# MSS_RCM register map
Vendor: Texas Instruments
Peripheral module from a debugger description file (folder radar).
Registers are 32-bit, read-write, no defined reset value unless marked. A register's access mark holds for its fields unless they carry their own. Offsets are as the file gives them; lines under a group give offsets from that group; [hi:lo] are bit positions; {n}, {i} and the like mark numbered series; 'fields as' and 'values as' point back to an identical list; <NAME> marks a mode.

## MSS_RCM
0x04 SOFTRST1 access not given
  [7:0] CR4SYSRST — Write 0xAD to assert a MSS CR4 only reset.Self clearing By design reset will happen either lower 4 bit is 0XD or Upper four bit is 0xA.
0x08 SOFTRST2
  [31:24] VIMRST — Write 0xAD to assert a VIM only reset. By design reset will happen either lower 4 bit is 0XD or Upper four bit is 0xA.
0x0C SOFTRST3
  [7:0] WDTRST — Write 0xAD to assert a WDT (RTI used for watch dog) only reset. By design reset will happen either lower 4 bit is 0XD or Upper four bit is 0xA.
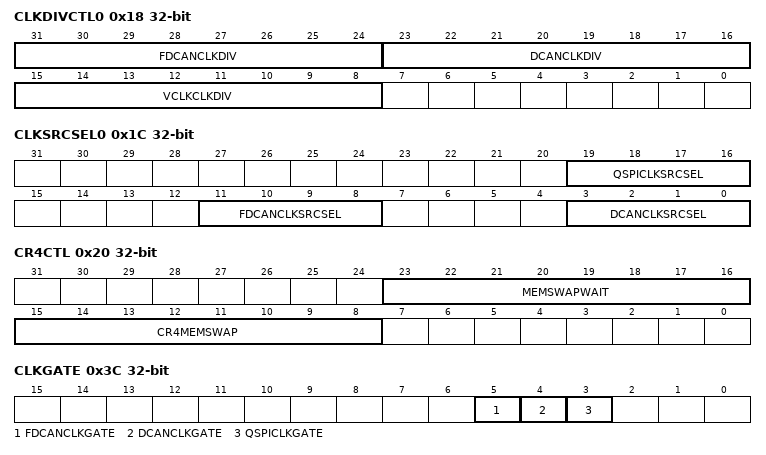
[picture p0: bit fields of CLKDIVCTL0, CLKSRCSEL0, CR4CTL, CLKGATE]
0x18 CLKDIVCTL0
  [31:24] FDCANCLKDIV — Divide value for FDCAN source clock selected by field FDCANCLKSRCSEL in register CLKSRCSEL0 0000_0000 => div1 0000_0001 => div2 | | 1111_1111 => div256
  [23:16] DCANCLKDIV — Divide value for DCAN source clock selected by field DCANCLKSRCSEL in register CLKSRCSEL0 0000_0000 => div1 0000_0001 => div2 | | 1111_1111 => div256
  [15:8] VCLKCLKDIV — Divide value for MSS subsystem source clock selected by field VCLKCLKSRCSEL in register CLKSRCSEL1 0000_0000 => div1 0000_0001 => div2 | | 1111_1111 => div256
0x1C CLKSRCSEL0
  [19:16] QSPICLKSRCSEL — Select clock source for QSPI baud clock 000 => VCLK 001 => RCCLK (10Mhz) 010 => 600Mhz PLL divided clock 011 => 240Mhz PLL divided clock 100 => CPUCLK 101 => RCCLK 110 => REFCLK from ANA (40Mhz or 50 Mhz or 80Mh or 100Mh) 111 => RCCLK
  [11:8] FDCANCLKSRCSEL — Select clock source for FDCANCLKSRCSEL 000 => VCLK 001 => RCCLK (10Mhz) 010 => 600Mhz PLL divided clock 011 => 240Mhz PLL divided clock 100 => CPUCLK 101 => RCCLK 110 => REFCLK from ANA 111 => RCCLK
  [3:0] DCANCLKSRCSEL — Select clock source for DCAN 000 => VCLK 001 => RCCLK (10Mhz) 010 => 600Mhz PLL divided clock 011 => 240Mhz PLL divided clock 100 => CPUCLK 101 => RCCLK 110 => REFCLK from ANA (40Mhz or 50 Mhz or 80Mh or 100Mh) 111 => RCCLK
0x20 CR4CTL
  [23:16] MEMSWAPWAIT — When CR4MEMSWAP is 0xAD : Write 0xAD to this field enable the CR4MEMSWAP only after a CR4 reset – either by writing to CR4SYSRST or by writing to PRCR register in CR4 debug space.
  [15:8] CR4MEMSWAP — Write 0xAD will map the MSS CR4 0x0000_0000 to MSS CR4 TCMA RAM start address.
0x3C CLKGATE
  [5] FDCANCLKGATE — Pre clock divider gate for FDCAN clock. Gates the clock before divider. Gates the clock before divider. 1: Gate the clock. 0: Ungate the clock.
  [4] DCANCLKGATE — Pre clock divider gate for DCAN clock. Gates the clock before divider. Gates the clock before divider. 1: Gate the clock. 0: Ungate the clock.
  [3] QSPICLKGATE — Pre clock divider gate for QSPI clock. Gates the clock before divider. Gates the clock before divider. 1: Gate the clock. 0: Ungate the clock.
0x44 CLKSRCSEL1
  [3:0] VCLKCLKSRCSEL — Select clock source for MSS subsystem VCLK 000 =>CPUCLK from ANA(XTAL 40Mhz or 50 Mhz or 80Mh or 100Mhz/ RCCLK in WU limp mode) 001 => RCCLK (10Mhz) 010 => 600Mhz PLL divided clock 011 => 240Mhz PLL divided clock 100 => RCCLK (10Mhz) 101 => RCCLK (10Mhz) 110 => REFCLK from ANA (40Mhz or 50 Mhz or 80Mh or 100Mh) 111 => RCCLK(10Mhz)
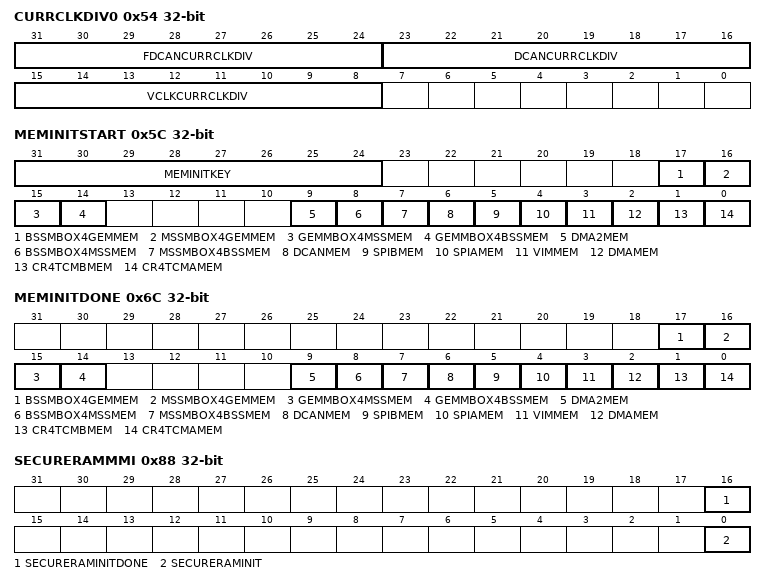
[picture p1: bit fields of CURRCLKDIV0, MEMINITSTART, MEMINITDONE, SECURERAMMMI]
0x54 CURRCLKDIV0 ro
  [31:24] FDCANCURRCLKDIV — Returns Current divide value of FDCAN baud clock divider.
  [23:16] DCANCURRCLKDIV — Returns Current divide value of DCAN baud clock divider.
  [15:8] VCLKCURRCLKDIV — Returns Current divide value of VCLK divider.
0x5C MEMINITSTART access not given
  [31:24] MEMINITKEY rw — Memory hardware initialization global enable key. Write 0XAD to enable MEMINIT.
  [17] BSSMBOX4GEMMEM — Writing '1' will trigger DSS- BSS mailbox initialization.Self clearing
  [16] MSSMBOX4GEMMEM — Writing '1' will trigger DSS- MSS mailbox initialization.Self clearing
  [15] GEMMBOX4MSSMEM — Writing '1' will trigger DSS- MSS mailbox initialization.Self clearing
  [14] GEMMBOX4BSSMEM — Writing '1' will trigger DSS- BSS mailbox initialization.Self clearing
  [9] DMA2MEM — Writing '1' will trigger DMA2 memory initialization.Self clearing
  [8] BSSMBOX4MSSMEM — Writing '1' will trigger MSS- BSS mailbox initialization.Self clearing
  [7] MSSMBOX4BSSMEM — Writing '1' will trigger MSS- BSS mailbox initialization.Self clearing
  [6] DCANMEM — Writing '1' will trigger DCAN memory initialization.Self clearing
  [5] SPIBMEM — Writing '1' will trigger SPIB memory initialization.Self clearing
  [4] SPIAMEM — Writing '1' will trigger SPIA memory initialization.Self clearing
  [3] VIMMEM — Writing '1' will trigger VIM memory initialization.Self clearing
  [2] DMAMEM — Writing '1' will trigger DMA memory initialization.Self clearing
  [1] CR4TCMBMEM — Writing '1' will trigger MSS TCMB memory initialization.Self clearing
  [0] CR4TCMAMEM — Writing '1' will trigger MSS TCMA memory initialization.Self clearing
0x60 CURRCLKDIV1 ro
  [7:0] QSPICURRCLKDIV — Returns Current divide value of QSPI_CLK divider.
0x6C MEMINITDONE ro
  [17] BSSMBOX4GEMMEM — Memory Initialization done status for DSS- BSS mailbox
  [16] MSSMBOX4GEMMEM — Memory Initialization done status for DSS- MSS mailbox
  [15] GEMMBOX4MSSMEM — Memory Initialization done status for DSS- MSS mailbox
  [14] GEMMBOX4BSSMEM — Memory Initialization done status for DSS- BSS mailbox
  [9] DMA2MEM — Memory Initialization done status for MSS DMA2 memory
  [8] BSSMBOX4MSSMEM — Memory Initialization done status for MSS- BSS mailbox
  [7] MSSMBOX4BSSMEM — Memory Initialization done status for MSS- BSS mailbox
  [6] DCANMEM — Memory Initialization done status for DCAN memory
  [5] SPIBMEM — Memory Initialization done status for MSS SPIB memory
  [4] SPIAMEM — Memory Initialization done status for MSS SPIA memory
  [3] VIMMEM — Memory Initialization done status for MSS VIM memory
  [2] DMAMEM — Memory Initialization done status for MSS DMA memory
  [1] CR4TCMBMEM — Memory Initialization done status for MSS TCMB memory
  [0] CR4TCMAMEM — Memory Initialization done status for MSS TCMA memory
0x70 ECCENMSSGEM
  [31:0] ECCENMSSGEM — 7:0 : Writing 0xAD will enable ECC for MSS- DSS mailbox 15:8: Writing 0xAD will enable ECC for MSS- DSS mailbox 18:16 : Write 3'b111 to clear the Address captured because of ECC error in MSS mailbox for GEM 21:19: Write 3'b111 to clear the Address captured because of ECC error. In GEM mailbox for MSS
0x74 ECCCAPTMSSGEM ro
  [31:0] ECCCAPTMSSGEM — 7:0 : mss_mbox4gem_ecc_fault_address 14:8 : mss_mbox4gem_repaired_bit 23:16 : gem_mbox4mss_ecc_fault_address 30:24 : gem_mbox4mss_repaired_bit
0x78 ECCENBSSGEM
  [31:0] ECCENBSSGEM — 7:0 : Writing 0xAD will enable ECC for DSS- BSS mailbox 15:8: Writing 0xAD will enable ECC for DSS- BSS mailbox 18:16 : Write 3'b111 to clear the Address captured because of ECC error in GEM mailbox for BSS 21:19: Write 3'b111 to clear the Address captured because of ECC error in BSS mailbox for GEM
0x7C ECCCAPTBSSGEM ro
  [31:0] ECCCAPTBSSGEM — 7:0 : bss_mbox4gem_ecc_fault_address 14:8 : bss_mbox4gem_repaired_bit 23:16 : gem_mbox4bss_ecc_fault_address 30:24 : gem_mbox4bss_repaired_bit
0x80 USERMODEEN
  [31:0] USERMODEEN — Write 0XADADADAD to enable user mode write access to MSS RCM space.
0x84 NSYSPERUSERMODEN
  [31:0] NSYSPERUSERMODEN — 2:0 : Write 3'b111 to enable user mode access to SPIA 5:3 : Write 3'b111 to enable user mode access to SPIB 10:8 : Write 3'b111 to enable user mode access to GIO 13:11 : Write 3'b111 to enable user mode access to QSPI 18:16 : Write 3'b111 to enable user mode access to SCIA 21:19 : Write 3'b111 to enable user mode access to SCIB 26:24 : Write 3'b111 to enable user mode access to DCAN
0x88 SECURERAMMMI access not given
  [16] SECURERAMINITDONE ro — Memory Initialization done status for Secure Key RAM
  [0] SECURERAMINIT — Writing '1' will trigger Secure Key RAM memory initialization.Self clearing
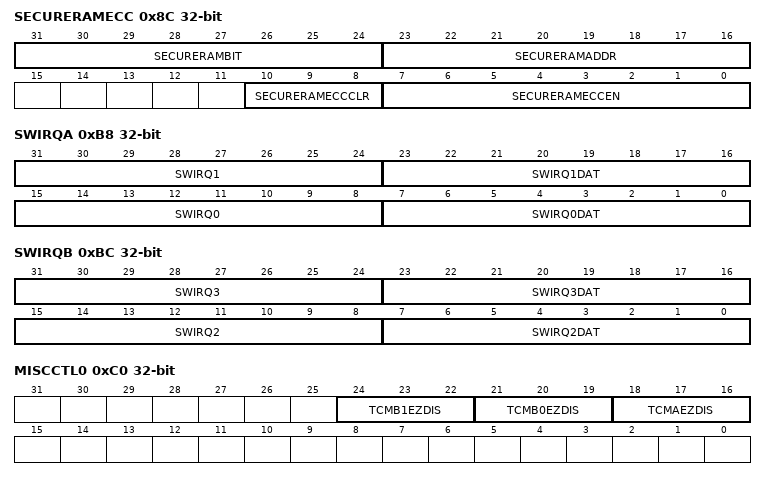
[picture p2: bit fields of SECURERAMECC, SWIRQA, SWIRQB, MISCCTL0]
0x8C SECURERAMECC access per field
  [31:24] SECURERAMBIT ro — Secure key RAM repaired bit
  [23:16] SECURERAMADDR ro — Secure Key RAM_ecc_fault_address
  [10:8] SECURERAMECCCLR rw — 10:8 : Write 3'b111 to clear the Address captured because of ECC error
  [7:0] SECURERAMECCEN rw — 7:0 : Writing 0xAD will enable ECC for Secure key RAM
{0x90+4i} ESMGATE{i} (i=0..2)
  [31:0] ESMGATE{i} — write 4'b111 to Gate [3:0] : Gate ESM group2 line {8i} [7:4] : Gate ESM group2 line {8i+1} [11:8] : Gate ESM group2 line {8i+2} [15:12] : Gate ESM group2 line {8i+3} [19:16] : Gate ESM group2 line {8i+4} [23:20] : Gate ESM group2 line {8i+5} [27:24] : Gate ESM group2 line {8i+6} [31:28] : Gate ESM group2 line {8i+7} Static register setting.Should not be changed on the fly
0x9C ESMGATE3
  [31:0] ESMGATE3 — write 4'b111 to Gate [3:0] : Gate ESM group2 line 16 [7:4] : Gate ESM group2 line 17 [11:8] : Gate ESM group2 line 18 [15:12] : Gate ESM group2 line 19 [19:16] : Gate ESM group2 line 20 [23:20] : Gate ESM group2 line 21 [27:24] : Gate ESM group2 line 22 [31:28] : Gate ESM group2 line 23 Static register setting.Should not be changed on the fly
0xA0 ESMGATE4
  [31:0] ESMGATE4 — write 4'b111 to Gate [3:0] : Gate ESM group3 line 0 [7:4] : Gate ESM group3 line 1 [11:8] : Gate ESM group3 line 2 [15:12] : Gate ESM group3 line 3 [19:16] : Gate ESM group3 line 4 [23:20] : Gate ESM group3 line 5 [27:24] : Gate ESM group3 line 6 [31:28] : Gate ESM group3 line 7 Static register setting.Should not be changed on the fly
0xAC KEY
  [31:0] KEY — Kicker Register. The value 83E7_83E7h must be written as part of the process to unlock the CPU write access to the MSS RCM registers
0xB8 SWIRQA
  [31:24] SWIRQ1 — Write 0XAD to trigger interrupt.
  [23:16] SWIRQ1DAT — Not Used.Reserved
  [15:8] SWIRQ0 — Write 0XAD to trigger interrupt.
  [7:0] SWIRQ0DAT — Not Used.Reserved
0xBC SWIRQB
  [31:24] SWIRQ3 — Write 0XAD to trigger interrupt.
  [23:16] SWIRQ3DAT — Not Used.Reserved
  [15:8] SWIRQ2 — Write 0XAD to trigger interrupt.
  [7:0] SWIRQ2DAT — Not Used.Reserved
0xC0 MISCCTL0
  [24:22] TCMB1EZDIS — Write 111 to make TCMB1 EZ to '1' regardless of Functional value.
  [21:19] TCMB0EZDIS — Write 111 to make TCMB0 EZ to '1' regardless of Functional value.
  [18:16] TCMAEZDIS — Write 111 to make TCMA EZ to '1' regardless of Functional value.
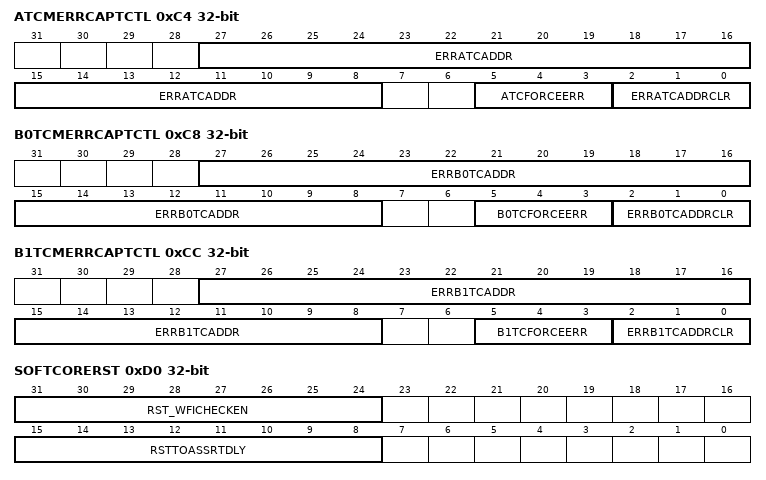
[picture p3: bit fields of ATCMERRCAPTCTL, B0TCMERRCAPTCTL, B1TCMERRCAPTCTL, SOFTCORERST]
0xC4 ATCMERRCAPTCTL access not given
  [27:8] ERRATCADDR ro — TCM address for which parity error happened
  [5:3] ATCFORCEERR rw — Write 111 to force error in TCM address control parity check logic.
  [2:0] ERRATCADDRCLR — When parity error happens on TCM address control path, Latch that captures the address for which error happened is disabled. Write 111 to re-enable the latching.Self clearing
0xC8 B0TCMERRCAPTCTL access not given
  [27:8] ERRB0TCADDR ro — TCM address for which parity error happened
  [5:3] B0TCFORCEERR rw — Write 111 to force error in TCM address control parity check logic.
  [2:0] ERRB0TCADDRCLR — When parity error happens on TCM address control path, Latch that captures the address for which error happened is disabled. Write 111 to re-enable the latching.Self clearing
0xCC B1TCMERRCAPTCTL access not given
  [27:8] ERRB1TCADDR ro — TCM address for which parity error happened
  [5:3] B1TCFORCEERR rw — Write 111 to force error in TCM address control parity check logic.
  [2:0] ERRB1TCADDRCLR — When parity error happens on TCM address control path, Latch that captures the address for which error happened is disabled. Write 111 to re-enable the latching.Self clearing
0xD0 SOFTCORERST
  [31:24] RST_WFICHECKEN — 0xAD : When CR4SYSRST is set, Before asserting the reset to CR4 wait for CR4 to enter WFI. 0X0: Dont wait for WFI
  [15:8] RSTTOASSRTDLY — Wait for programmed number of clock cycle before reset is asserted to CR4.
0xD8 RSTCAUSE ro
  [7:0] RSTCAUSE — Gives cause of MSS reset 0000_1001 : System out of NRESET 0000_1000 : Warm Reset 0000_0010 : MSS only Wdog Reset. 0000_0100 : MSS subsystem reset because of Software trigger. 0010_0000 : CR4 reset because of Software trigger. 0001_0000 : STC reset 0100_0000 : CR4 reset because of writing to PRCR register in CR4 debug space. 1000_0000 : CR4 only Wdog reset
0xDC RSTCAUSECLR access not given
  [7:0] RSTCAUSECLR — Write 0xAD to clear RSTCAUSE.Self clearing
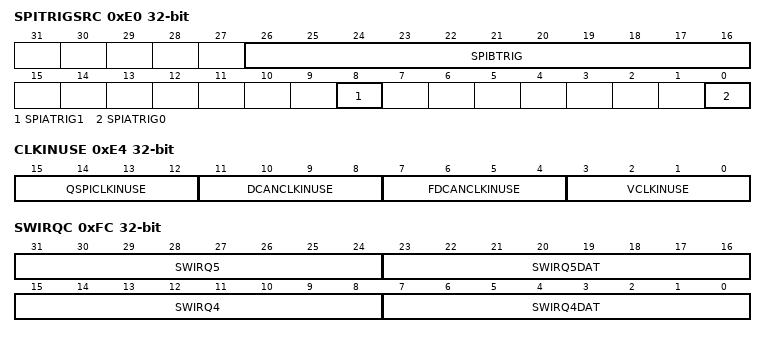
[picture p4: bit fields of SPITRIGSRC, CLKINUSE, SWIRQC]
0xE0 SPITRIGSRC
  [26:16] SPIBTRIG — [20:16] --> Trigger sources for MIBSPIB
  [8] SPIATRIG1 — 1st bit ofTRG_SRC input of SPIA.
  [0] SPIATRIG0 — 0th bit ofTRG_SRC input of SPIA.
0xE4 CLKINUSE ro
  [15:12] QSPICLKINUSE — Current Clock Source Select Mux value for QSPI CLK 000 => VCLK 001 => RCCLK (10Mhz) 010 => 600Mhz PLL divided clock 011 => 240Mhz PLL divided clock 100 => CPUCLK 101 => RCCLK 110 => REFCLK 111 => RCCLK (10Mhz)
  [11:8] DCANCLKINUSE — Current Clock Source Select Mux value for DCAN CLK 000 => VCLK 001 => RCCLK (10Mhz) 010 => 600Mhz PLL divided clock 011 => 240Mhz PLL divided clock 100 => CPUCLK 101 => RCCLK 110 => REFCLK 111 => RCCLK (10Mhz)
  [7:4] FDCANCLKINUSE — Current Clock Source Select Mux value for FDCAN CLK 000 => VCLK 001 => RCCLK (10Mhz) 010 => 600Mhz PLL divided clock 011 => 240Mhz PLL divided clock 100 => CPUCLK 101 => RCCLK 110 => REFCLK 111 => RCCLK (10Mhz)
  [3:0] VCLKINUSE — Current Clock Source Select Mux value for VCLK 000 => CPUCLK (40Mhz or 50 Mhz or 80Mh or 100Mh) 001 => RCCLK (10Mhz) 010 => 600Mhz PLL divided clock 011 => 240Mhz PLL divided clock 101 => RCCLK (10Mhz) 110 => REFCLK 111 => RCCLK (10Mhz)
0xE8 ECCENMSSBSS
  [31:0] ECCENMSSBSS — 7:0 : Writing 0xAD will enable ECC for MSS – BSS mailbox 15:8: Writing 0xAD will enable ECC for MSS – BSS mailbox 18:16 : Write 3'b111 to clear the Address captured because of ECC error in MSS mailbox for BSS 21:19: Write 3'b111 to clear the Address captured because of ECC error. In BSS mailbox for MSS
0xEC ECCCAPTMSSBSS ro
  [31:0] ECCCAPTMSSBSS — 7:0 : mss_mbox4bss_ecc_fault_address 14:8 : mss_mbox4bss_repaired_bit 23:16 : bss_mbox4mss_ecc_fault_address 30:24 : bss_mbox4mss_repaired_bit
0xF0 CLKDIVCTL2
  [7:0] QSPICLKDIV — Divide value for QSPI baud clock selected by field QSPICLKSRCSEL in register CLKSRCSEL0 0000_0000 => div1 0000_0001 => div2 | | 1111_1111 => div256
0xFC SWIRQC
  [31:24] SWIRQ5 — Write 0XAD to trigger interrupt.
  [23:16] SWIRQ5DAT — Not Used.Reserved
  [15:8] SWIRQ4 — Write 0XAD to trigger interrupt.
  [7:0] SWIRQ4DAT — Not Used.Reserved
